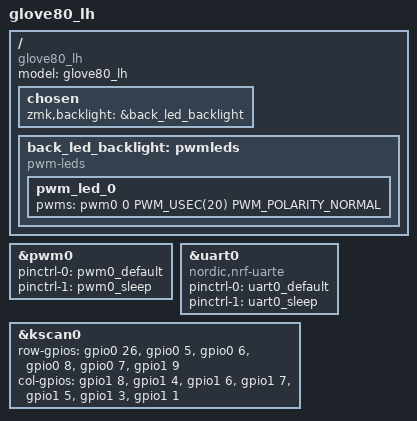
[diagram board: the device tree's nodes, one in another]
/*
 * Copyright (c) 2021 The ZMK Contributors
 *
 * SPDX-License-Identifier: MIT
 */

#include "glove80_dongle.dtsi"
#include "glove80_dongle-pinctrl.dtsi"

#include <dt-bindings/led/led.h>

/ {
    model = "glove80_lh";
    compatible = "glove80_lh";

    chosen {
        zmk,backlight = &back_led_backlight;
    };

    back_led_backlight: pwmleds {
        compatible = "pwm-leds";
        pwm_led_0 {
            pwms = <&pwm0 0 PWM_USEC(20) PWM_POLARITY_NORMAL>;
        };
    };
};

&pwm0 {
    status = "okay";
    pinctrl-0 = <&pwm0_default>;
    pinctrl-1 = <&pwm0_sleep>;
    pinctrl-names = "default", "sleep";
};

&uart0 {
    compatible = "nordic,nrf-uarte";
    pinctrl-0 = <&uart0_default>;
    pinctrl-1 = <&uart0_sleep>;
    pinctrl-names = "default", "sleep";
};

&kscan0 {
    row-gpios
        = <&gpio0 26 (GPIO_ACTIVE_HIGH | GPIO_PULL_DOWN)> // LH ROW1
        , <&gpio0 5 (GPIO_ACTIVE_HIGH | GPIO_PULL_DOWN)> // LH ROW2
        , <&gpio0 6 (GPIO_ACTIVE_HIGH | GPIO_PULL_DOWN)> // LH ROW3
        , <&gpio0 8 (GPIO_ACTIVE_HIGH | GPIO_PULL_DOWN)> // LH ROW4
        , <&gpio0 7 (GPIO_ACTIVE_HIGH | GPIO_PULL_DOWN)> // LH ROW5
        , <&gpio1 9 (GPIO_ACTIVE_HIGH | GPIO_PULL_DOWN)> // LH ROW6
        ;
    col-gpios
        = <&gpio1 8 GPIO_ACTIVE_HIGH> // LH COL6
        , <&gpio1 4 GPIO_ACTIVE_HIGH> // LH COL5
        , <&gpio1 6 GPIO_ACTIVE_HIGH> // LH COL4
        , <&gpio1 7 GPIO_ACTIVE_HIGH> // LH COL3
        , <&gpio1 5 GPIO_ACTIVE_HIGH> // LH COL2
        , <&gpio1 3 GPIO_ACTIVE_HIGH> // LH COL1
        , <&gpio1 1 GPIO_ACTIVE_HIGH> // LH Thumb
        ;
};
